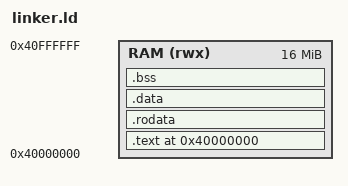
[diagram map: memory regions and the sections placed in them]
/* Linker script for MEL ARM64 64-bit Hello UART Boot Payload */
OUTPUT_ARCH("aarch64")
ENTRY(_start)

MEMORY
{
    RAM (rwx) : ORIGIN = 0x40000000, LENGTH = 16M
}

SECTIONS
{
    . = 0x40000000;

    .text : {
        *(.text.boot)
        *(.text*)
    } > RAM

    .rodata : {
        *(.rodata*)
    } > RAM

    .data : {
        *(.data*)
    } > RAM

    .bss : {
        *(.bss*)
    } > RAM

    /DISCARD/ : {
        *(.comment)
        *(.note*)
        *(.eh_frame)
    }
}
